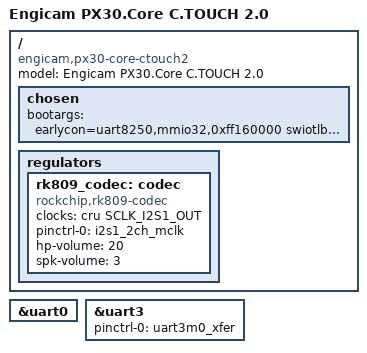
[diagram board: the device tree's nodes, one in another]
// SPDX-License-Identifier: (GPL-2.0+ OR MIT)
/*
 * Copyright (c) 2020 Fuzhou Rockchip Electronics Co., Ltd
 * Copyright (c) 2020 Engicam srl
 * Copyright (c) 2020 Amarula Solutions
 * Copyright (c) 2020 Amarula Solutions(India)
 */

/dts-v1/;
#include "px30.dtsi"
#include "px30-engicam-ctouch2.dtsi"
#include "px30-engicam-px30-core.dtsi"

/ {
	model = "Engicam PX30.Core C.TOUCH 2.0";
	compatible = "engicam,px30-core-ctouch2", "engicam,px30-core",
		     "rockchip,px30";

	chosen {
		bootargs = "earlycon=uart8250,mmio32,0xff160000 swiotlb=1 console=ttyS2,115200n8 rw root=PARTUUID=614e0000-0000 rootwait";
	};

	regulators{
		rk809_codec: codec {
			#sound-dai-cells = <0>;
			compatible = "rockchip,rk809-codec", "rockchip,rk817-codec";
			clocks = <&cru SCLK_I2S1_OUT>;
			clock-names = "mclk";
			pinctrl-names = "default";
			pinctrl-0 = <&i2s1_2ch_mclk>;
			hp-volume = <20>;
			spk-volume = <3>;
			status = "okay";
		};
	};
};

/* RS485 */
&uart0 {
	status= "okay";
};
/* RS232 */
&uart3 {
	pinctrl-0 = <&uart3m0_xfer>;
	status= "okay";
};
